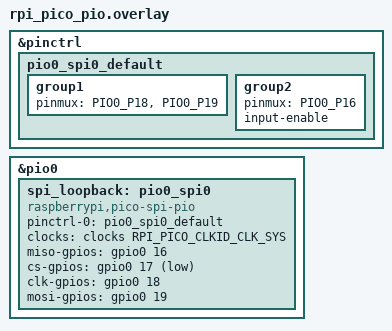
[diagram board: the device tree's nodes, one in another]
/*
 * Copyright (c) 2024 The Zephyr Project Contributors
 *
 * SPDX-License-Identifier: Apache-2.0
 */

#define SPI_LOOPBACK_FAST_HZ 14000000

&pinctrl {
	pio0_spi0_default: pio0_spi0_default {
		/* gpio 17 is used for chip select, not assigned to the PIO */
		group1 {
			pinmux = <PIO0_P18>, <PIO0_P19>;
		};

		group2 {
			pinmux = <PIO0_P16>;
			input-enable;
		};
	};
};

&pio0 {
	status = "okay";

	spi_loopback: pio0_spi0: pio0_spi0 {
		pinctrl-0 = <&pio0_spi0_default>;
		pinctrl-names = "default";

		compatible = "raspberrypi,pico-spi-pio";
		status = "okay";
		#address-cells = <1>;
		#size-cells = <0>;
		clocks = <&clocks RPI_PICO_CLKID_CLK_SYS>;
		miso-gpios = <&gpio0 16 0>;
		cs-gpios = <&gpio0 17 GPIO_ACTIVE_LOW>;
		clk-gpios = <&gpio0 18 GPIO_ACTIVE_HIGH>;
		mosi-gpios = <&gpio0 19 GPIO_ACTIVE_HIGH>;
	};
};

#include "../spi-loopback.dtsi"
